# nrf9230_engb_application register map
Vendor: Nordic Semiconductor; Series: nRF92; File version: 1
CPU: CM33 r0p4, little endian, MPU, FPU, 3 interrupt priority bits, 480 interrupts, 4 SAU regions
Registers are 32-bit, read-write, reset 0x0 unless marked. A register's access mark holds for its fields unless they carry their own. Offsets are from the block's base; [hi:lo] are bit positions; 'fields as' and 'values as' point back to an identical list.

## GLOBAL_MCAN120_NS — MCAN 0
Base 0x2FBEF800; alternate view of GLOBAL_DMU120_NS
Same registers: GLOBAL_MCAN121_NS 0x2FBF7800 (alternate view of GLOBAL_DMU121_NS)
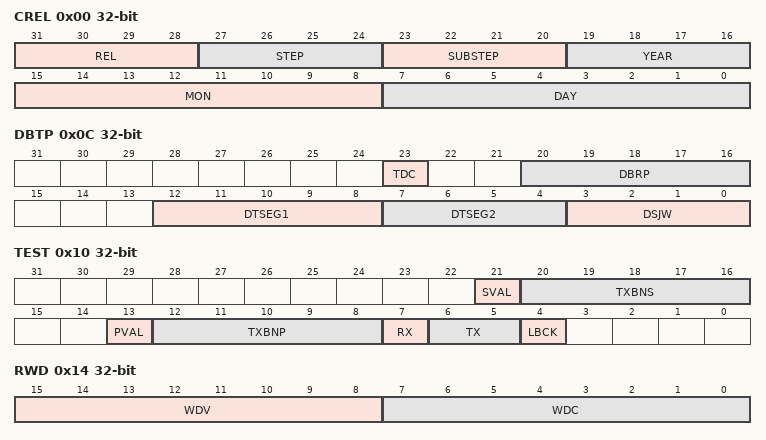
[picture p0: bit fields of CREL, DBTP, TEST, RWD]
0x00 CREL ro — Core Release Register
  [31:28] REL — Core Release
  [27:24] STEP — Step of Core Release
  [23:20] SUBSTEP — Sub-step of Core Release
  [19:16] YEAR — Time Stamp Year
  [15:8] MON — Time Stamp Month
  [7:0] DAY — Time Stamp Day
0x04 ENDN ro — Endian Register
  [31:0] ETV — Endianness Test Value
0x08 CUST — Customer Register
0x0C DBTP — Data Bit Timing and Prescaler Register
  [23] TDC — Transmitter Delay Compensation
    0=Disabled (Unspecified); 1=Enabled (Unspecified)
  [20:16] DBRP — Data Bit Rate Prescaler
  [12:8] DTSEG1 — Data time segment before sample point
  [7:4] DTSEG2 — Data time segment after sample point
  [3:0] DSJW — Data (Re)Synchronization Jump Width
0x10 TEST
  [21] SVAL — Started Valid
    0=NotValid (Value of TXBNP not valid); 1=Valid (Value of TXBNP valid)
  [20:16] TXBNS — Tx Buffer Number Started
  [13] PVAL — Prepared Valid
    values as SVAL
  [12:8] TXBNP — Tx Buffer Number Prepared
  [7] RX — Receive Pin
    0=Dominant (The CAN bus is dominant (m_can_rx = 0)); 1=Recessive (The CAN bus is recessive (m_can_rx = '1'))
  [6:5] TX — Control of Transmit Pin
    0=CanCore (controlled by the CAN Core, updated at the end of the CAN bit time); 1=Monitored (Sample Point can be monitored at pin m_can_tx); 2=Dominant (0) level at pin m_can_tx; 3=Recessive (1) at pin m_can_tx
  [4] LBCK — Loop Back Mode
    0=Disabled (Loop Back Mode is disabled); 1=Enabled (Loop Back Mode is enabled)
0x14 RWD — RAM Watchdog
  [15:8] WDV — Actual Message RAM Watchdog Counter Value.
  [7:0] WDC — Start value of the Message RAM Watchdog Counter. With the reset value of '00' the counter is disabled.
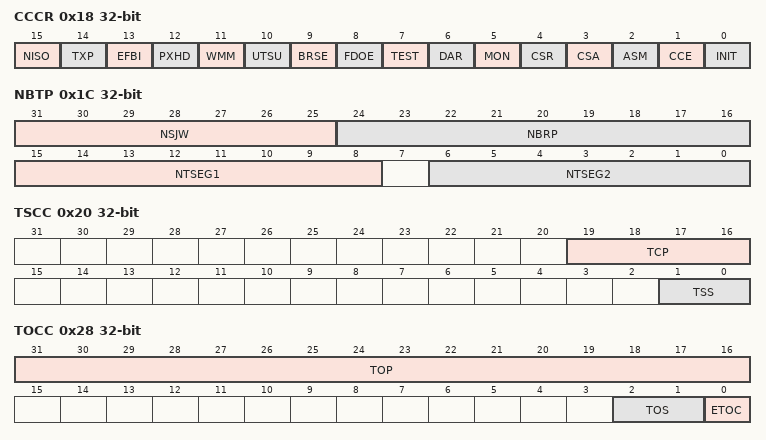
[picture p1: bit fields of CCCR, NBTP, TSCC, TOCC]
0x18 CCCR — CC Control Register
  [15] NISO — Non ISO Operation
    0=Disabled (CAN FD frame format according to ISO 11898-1:2015); 1=Enabled (CAN FD frame format according to Bosch CAN FD Specification V1.0)
  [14] TXP — Transmit Pause
    0=Disabled (Transmit pause disabled); 1=Enabled (Transmit pause enabled)
  [13] EFBI — Edge Filtering during Bus Integration
    0=Disabled (Edge filtering disabled); 1=Enabled (Two consecutive dominant tq required to detect an edge for hard synchronization)
  [12] PXHD — Protocol Exception Handling Disable
    0=Enabled (Protocol exception handling enabled); 1=Disabled (Protocol exception handling disabled)
  [11] WMM — Wide Message Marker
    0=Disabled (8-bit Message Marker used); 1=Enabled (16-bit Message Marker used, replacing 16-bit timestamps in Tx Event FIFO)
  [10] UTSU — Use Timestamping Unit
    0=Disabled (Internal time stamping); 1=Enabled (External time stamping by TSU)
  [9] BRSE — Bit Rate Switch Enable
    0=Disabled (Bit rate switching for transmissions disabled); 1=Enabled (Bit rate switching for transmissions enabled)
  [8] FDOE — FD Operation Enable
    0=Disabled (FD operation disabled); 1=Enabled (FD operation enabled)
  [7] TEST — Test Mode Enable
    0=Disabled (Normal operation, register TEST holds reset values); 1=Enabled (Test Mode, write access to register TEST enabled)
  [6] DAR — Disable Automatic Retransmission
    0=Enabled (Automatic retransmission of messages not transmitted successfully enabled); 1=Disabled (Automatic retransmission disabled)
  [5] MON — Bus Monitoring Mode
    0=Disabled (Bus Monitoring Mode is disabled); 1=Enabled (Bus Monitoring Mode is enabled)
  [4] CSR — Clock Stop Request
    0=Disabled (No clock stop is requested); 1=Enabled (Clock stop requested.)
  [3] CSA — Clock Stop Acknowledge
    0=Disabled (No clock stop acknowledged); 1=Enabled (MCAN may be set in power down by stopping m_can_hclk and m_can_cclk)
  [2] ASM — Restricted Operation Mode
    0=Disabled (Normal CAN operation); 1=Enabled (Restricted Operation Mode active)
  [1] CCE — Configuration Change Enable
    0=Disabled (The CPU has no write access to the protected configuration registers); 1=Enabled (The CPU has write access to the protected configuration registers (while CCCR.INIT = '1'))
  [0] INIT — Initialization
    0=Normal Operation; 1=Initialization is started
0x1C NBTP — Nominal Bit Timing and Prescaler Register
  [31:25] NSJW — Nominal (Re)Synchronization Jump Width
  [24:16] NBRP — Nominal Bit Rate Prescaler
  [15:8] NTSEG1 — Nominal Time segment before sample point
  [6:0] NTSEG2 — Nominal Time segment after sample point
0x20 TSCC — Timestamp Counter Configuration
  [19:16] TCP — Timestamp Counter Prescaler
  [1:0] TSS — Timestamp Select
    0=Zero (Timestamp counter value always 0x0000); 1=Increment (Timestamp counter value incremented according to TCP); 2=External timestamp counter value used; 3=Zero0 (Same as Zero)
0x24 TSCV — Timestamp Counter Value
  [15:0] TSC — Timestamp Counter
0x28 TOCC — Timeout Counter Configuration
  [31:16] TOP — Timeout Period
  [2:1] TOS — Timeout Select
    0=Continuous operation; 1=TxEvent (Timeout controlled by Tx Event FIFO); 2=RxFifo0 (Timeout controlled by Rx FIFO 0); 3=RxFifo1 (Timeout controlled by Rx FIFO 1)
  [0] ETOC — Enable Timeout Counter
    0=Disabled (Timeout Counter disabled); 1=Enabled (Timeout Counter enabled)
0x2C TOCV — Timeout Counter Value
  [15:0] TOC — Timeout Counter
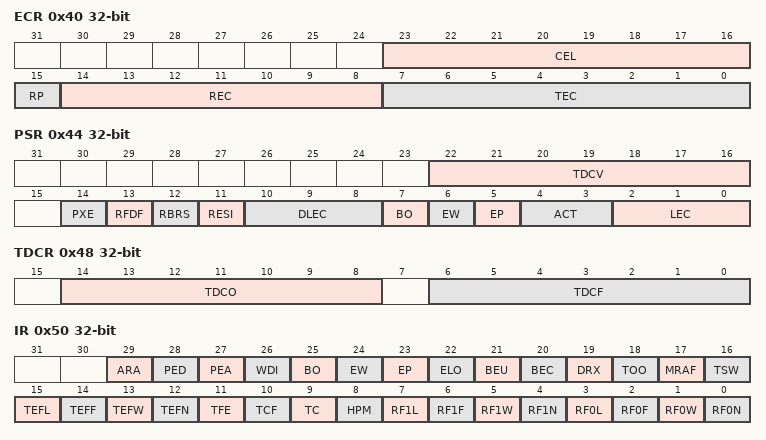
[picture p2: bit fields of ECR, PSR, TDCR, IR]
0x40 ECR — Error Counter Register
  [23:16] CEL — CAN Error Logging
  [15] RP — Receive Error Passive
    0=Below (The Receive Error Counter is below the error passive level of 128); 1=Reached (The Receive Error Counter has reached the error passive level of 128)
  [14:8] REC — Receive Error Counter
  [7:0] TEC — Transmit Error Counter
0x44 PSR — Protocol Status Register
  [22:16] TDCV — Transmitter Delay Compensation Value
  [14] PXE — Protocol Exception Event
    0=NotTriggered (No protocol exception event occurred since last read access); 1=Triggered (Protocol exception event occurred)
  [13] RFDF — Received a CAN FD Message
    0=NotReceived (Since this bit was reset by the CPU, no CAN FD message has been received); 1=Received (Message in CAN FD format with FDF flag set has been received)
  [12] RBRS — BRS flag of last received CAN FD Message
    0=NotReceived (Last received CAN FD message did not ha ve its BRS flag set); 1=Received (Last received CAN FD message had its BRS flag set)
  [11] RESI — ESI flag of last received CAN FD Message
    0=NotReceived (Last received CAN FD message did not ha ve its ESI flag set); 1=Received (Last received CAN FD message had its ESI flag set)
  [10:8] DLEC — Data Phase Last Error Code
  [7] BO — Bus_Off Status
    0=On (The MCAN is not Bus_Off); 1=Off (The MCAN is in Bus_Off state)
  [6] EW — Warning Status
    0=Below (Both error counters are below the Error_Warning limit of 96); 1=Reached (At least one of error counter has reached the Error_Warning limit of 96)
  [5] EP — Error Passive
    0=Active (The MCAN is in the Error_Active state. It normally takes part in bus communication and sends an active error flag when an error has been detected); 1=Passive (The MCAN is in the Error_Passive state)
  [4:3] ACT — Activity
    0=Synchronizing (Node is synchronizing on CAN communication); 1=Idle (Node is neither receiver nor tr ansmitter); 2=Receiver (Node is operating as receiver); 3=Transmitter (Node is operating as transmitter)
  [2:0] LEC — Last Error Code
    0=No error occurred since LEC has been reset by successful reception or transmission; 1=StuffError (More than 5 equal bits in a sequence have occurred in a part of a received message where this is not allowed.); 2=FormError (A fixed format part of a received frame has the wrong format.); 3=AckError (The message transmitted by the MCAN was not acknowledged by another node.); 4=Bit1Error (During the transmission of a message (with the exception of the arbitration field), the device wanted to send a recessive level (bit of logical value 1), but the monitored bus value was dominant.); 5=Bit0Error (During the transmission of a message (or acknowledge bit, or active error flag, or overload flag), the device wanted to send a dominant level (data or identifier bit logical value '0'), but the monitored bus value was recessive. During Bus_Off recovery this status is set each time a sequence of 11 recessive bits has been monitored. This enables the CPU to monitor the proceeding of the Bus_Off recovery sequence (indicating the bus is not stuck at dominant or continuously disturbed).); 6=CRCError (The CRC check sum of a received message was incorrect. The CRC of an incoming message does not match with the CRC calculated from the received data.); 7=NoChange (Any read access to the Protocol Status Register re-initializes the LEC to '7'. When the LEC shows the value '7', no CAN bus event was detected since the last CPU read access to the Protocol Status Register.)
0x48 TDCR — Transmitter Delay Compensation Register
  [14:8] TDCO — Transmitter Delay Compensation SSP Offset
  [6:0] TDCF — Transmitter Delay Compensation Filter Window Length
0x50 IR — Interrupt Register
  [29] ARA — Access to Reserved Address
    1=Clear (Write '1' to clear interrupt flag); 0=NotGenerated (No access to reserved address occurred); 1=Generated (Access to reserved address occurred)
  [28] PED — Protocol Error in Data Phase (Data Bit Time is used)
    1=Clear (Write '1' to clear interrupt flag); 0=NotGenerated (No protocol error in data phase); 1=Generated (Protocol error in data phase detected (PSR.DLEC ≠ 0,7))
  [27] PEA — Protocol Error in Arbitration Phase (Nominal Bit Time is used)
    1=Clear (Write '1' to clear interrupt flag); 0=NotGenerated (No protocol error in arbitration phase); 1=Generated (Protocol error in arbitration phase detected (PSR.LEC ≠ 0,7))
  [26] WDI — Watchdog Interrupt
    1=Clear (Write '1' to clear interrupt flag); 0=NotGenerated (No Message RAM Watchdog event occurred); 1=Generated (Message RAM Watchdog event due to missing READY)
  [25] BO — Bus_Off Status
    1=Clear (Write '1' to clear interrupt flag); 0=NotGenerated (Bus_Off status unchanged); 1=Generated (Bus_Off status changed)
  [24] EW — Warning Status
    1=Clear (Write '1' to clear interrupt flag); 0=NotGenerated (Error_Warning status unchanged); 1=Generated (Error_Warning status changed)
  [23] EP — Error Passive
    1=Clear (Write '1' to clear interrupt flag); 0=NotGenerated (Error_Passive status unchanged); 1=Generated (Error_Passive status changed)
  [22] ELO — Error Logging Overflow
    1=Clear (Write '1' to clear interrupt flag); 0=NotGenerated (CAN Error Logging Counter did not overflow); 1=Generated (Overflow of CAN Error Logging Counter occurred)
  [21] BEU — Bus Error Uncorrected
    1=Clear (Write '1' to clear interrupt flag); 0=NotGenerated (No read slave error detected when reading from Message RAM); 1=Generated (Read slave error detected)
  [20] BEC — Bit Error Corrected
    1=Clear (Write '1' to clear interrupt flag); 0=NotGenerated (No bit error detected when reading from Message RAM); 1=Generated (Bit error detected and corrected (e.g. ECC))
  [19] DRX — Message stored to Dedicated Rx Buffer
    1=Clear (Write '1' to clear interrupt flag); 0=NotGenerated (No Rx Buffer updated); 1=Generated (At least one received message stored into an Rx Buff er)
  [18] TOO — Timeout Occurred
    1=Clear (Write '1' to clear interrupt flag); 0=NotGenerated (No timeout); 1=Generated (Timeout reached)
  [17] MRAF — Message RAM Access Failure
    1=Clear (Write '1' to clear interrupt flag); 0=NotGenerated (No Message RAM access failure occurred); 1=Generated (Message RAM access failure occurred)
  [16] TSW — Timestamp Wraparound
    1=Clear (Write '1' to clear interrupt flag); 0=NotGenerated (No timestamp counter wrap-around); 1=Generated (Timestamp counter wrapped around)
  [15] TEFL — Tx Event FIFO Element Lost
    1=Clear (Write '1' to clear interrupt flag); 0=NotGenerated (No Tx Event FIFO element lost); 1=Generated (Tx Event FIFO element lost, also set after wr ite attempt to Tx Event FIFO of siz e zero)
  [14] TEFF — Tx Event FIFO Full
    1=Clear (Write '1' to clear interrupt flag); 0=NotGenerated (Tx Event FIFO not full); 1=Generated (Tx Event FIFO full)
  [13] TEFW — Tx Event FIFO Watermark Reached
    1=Clear (Write '1' to clear interrupt flag); 0=NotGenerated (Tx Event FIFO fill level below watermark); 1=Generated (Tx Event FIFO fill level reached watermark)
  [12] TEFN — Tx Event FIFO New Entry
    1=Clear (Write '1' to clear interrupt flag); 0=NotGenerated (Tx Event FIFO unchanged); 1=Generated (Tx Handler wrote Tx Event FIFO element)
  [11] TFE — Tx FIFO Empty
    1=Clear (Write '1' to clear interrupt flag); 0=NotGenerated (Tx FIFO non-empty); 1=Generated (Tx FIFO empty)
  [10] TCF — Transmission Cancellation Finished
    1=Clear (Write '1' to clear interrupt flag); 0=NotGenerated (No transmission cancellation finished); 1=Generated (Transmission cancellation finished)
  [9] TC — Transmission Completed
    1=Clear (Write '1' to clear interrupt flag); 0=NotGenerated (No transmission completed); 1=Generated (Transmission completed)
  [8] HPM — High Priority Message
    1=Clear (Write '1' to clear interrupt flag); 0=NotGenerated (No high priority message received); 1=Generated (High priority message received)
  [7] RF1L — Rx FIFO 1 Message Lost
    1=Clear (Write '1' to clear interrupt flag); 0=NotGenerated (No Rx FIFO 1 message lost); 1=Generated (Rx FIFO 1 message lost, also set after write attempt to Rx FIFO 1 of size zero)
  [6] RF1F — Rx FIFO 1 Full
    1=Clear (Write '1' to clear interrupt flag); 0=NotGenerated (Rx FIFO 1 not full); 1=Generated (Rx FIFO 1 full)
  [5] RF1W — Rx FIFO 1 Watermark Reached
    1=Clear (Write '1' to clear interrupt flag); 0=NotGenerated (Rx FIFO 1 fill level below watermark); 1=Generated (Rx FIFO 1 fill level reached watermark)
  [4] RF1N — Rx FIFO 1 New Message
    1=Clear (Write '1' to clear interrupt flag); 0=NotGenerated (No new message written to Rx FIFO 1); 1=Generated (New message written to Rx FIFO 1)
  [3] RF0L — Rx FIFO 0 Message Lost
    1=Clear (Write '1' to clear interrupt flag); 0=NotGenerated (No Rx FIFO 0 message lost); 1=Generated (Rx FIFO 0 message lost, also set after write attempt to Rx FIFO 0 of size zero)
  [2] RF0F — Rx FIFO 0 Full
    1=Clear (Write '1' to clear interrupt flag); 0=NotGenerated (Rx FIFO 0 not full); 1=Generated (Rx FIFO 0 full)
  [1] RF0W — Rx FIFO 0 Watermark Reached
    1=Clear (Write '1' to clear interrupt flag); 0=NotGenerated (Rx FIFO 0 fill level below watermark); 1=Generated (Rx FIFO 0 fill level reached watermark)
  [0] RF0N — Rx FIFO 0 New Message
    1=Clear (Write '1' to clear interrupt flag); 0=NotGenerated (No new message written to Rx FIFO 0); 1=Generated (New message written to Rx FIFO 0)
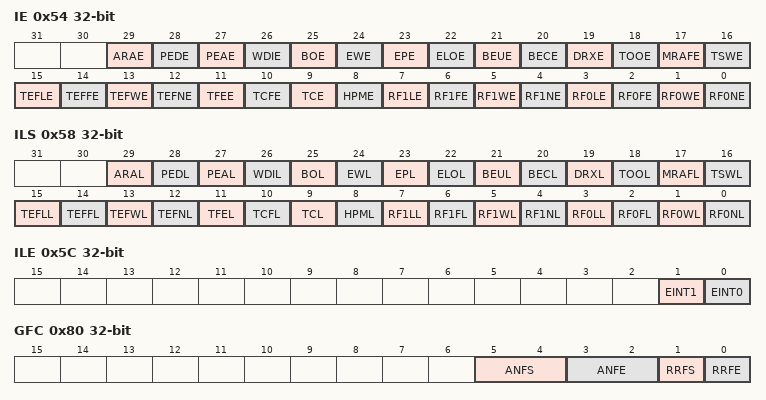
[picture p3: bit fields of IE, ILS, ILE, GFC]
0x54 IE — Interrupt Enable
  [all] fields
    0=Disable (Interrupt disabled.); 1=Enable (Interrupt enabled.)
  [29] ARAE — Access to Reserved Address Enable
  [28] PEDE — Protocol Error in Data Phase Enable
  [27] PEAE — Protocol Error in Arbitration Phase Enable
  [26] WDIE — Watchdog Interrupt Enable
  [25] BOE — Bus_Off Status Interrupt Enable
  [24] EWE — Warning Status Interrupt Enable
  [23] EPE — Error Passive Interrupt Enable
  [22] ELOE — Error Logging Overflow Interrupt Enable
  [21] BEUE — Bus Error Uncorrected Interrupt Enable
  [20] BECE — Bit Error Corrected Interrupt Enable
  [19] DRXE — Message stored to Dedicated Rx Buffer Interrupt Enable
  [18] TOOE — Timeout Occurred Interrupt Enable
  [17] MRAFE — Message RAM Access Failure Interrupt Enable
  [16] TSWE — Timestamp Wraparound Interrupt Enable
  [15] TEFLE — Tx Event FIFO Event Lost Interrupt Enable
  [14] TEFFE — Tx Event FIFO Full Interrupt Enable
  [13] TEFWE — Tx Event FIFO Watermark Reached Interrupt Enable
  [12] TEFNE — Tx Event FIFO New Entry Interrupt Enable
  [11] TFEE — Tx FIFO Empty Interrupt Enable
  [10] TCFE — Transmission Cancellation Finished Interrupt Enable
  [9] TCE — Transmission Completed Interrupt Enable
  [8] HPME — High Priority Message Interrupt Enable
  [7] RF1LE — Rx FIFO 1 Message Lost Interrupt Enable
  [6] RF1FE — Rx FIFO 1 Full Interrupt Enable
  [5] RF1WE — Rx FIFO 1 Watermark Reached Interrupt Enable
  [4] RF1NE — Rx FIFO 1 New Message Interrupt Enable
  [3] RF0LE — Rx FIFO 0 Message Lost Interrupt Enable
  [2] RF0FE — Rx FIFO 0 Full Interrupt Enable
  [1] RF0WE — Rx FIFO 0 Watermark Reached Interrupt Enable
  [0] RF0NE — Rx FIFO 0 New Message Interrupt Enable
0x58 ILS — Interrupt Line Select
  [all] fields
    0=Assigned0 (Interrupt assigned to interrupt line CORE0.); 1=Assigned1 (Interrupt assigned to interrupt line CORE1.)
  [29] ARAL — Access to Reserved Address Line
  [28] PEDL — Protocol Error in Data Phase Line
  [27] PEAL — Protocol Error in Arbitration Phase Line
  [26] WDIL — Watchdog Interrupt Line
  [25] BOL — Bus_Off Status Interrupt Line
  [24] EWL — Warning Status Interrupt Line
  [23] EPL — Error Passive Interrupt Line
  [22] ELOL — Error Logging Overflow Interrupt Line
  [21] BEUL — Bus Error Uncorrected Interrupt Line
  [20] BECL — Bit Error Corrected Interrupt Line
  [19] DRXL — Message stored to Dedicated Rx Buffer Interrupt Line
  [18] TOOL — Timeout Occurred Interrupt Line
  [17] MRAFL — Message RAM Access Failure Interrupt Line
  [16] TSWL — Timestamp Wraparound Interrupt Line
  [15] TEFLL — Tx Event FIFO Event Lost Interrupt Line
  [14] TEFFL — Tx Event FIFO Full Interrupt Line
  [13] TEFWL — Tx Event FIFO Watermark Reached Interrupt Line
  [12] TEFNL — Tx Event FIFO New Entry Interrupt Line
  [11] TFEL — Tx FIFO Empty Interrupt Line
  [10] TCFL — Transmission Cancellation Finished Interrupt Line
  [9] TCL — Transmission Completed Interrupt Line
  [8] HPML — High Priority Message Interrupt Line
  [7] RF1LL — Rx FIFO 1 Message Lost Interrupt Line
  [6] RF1FL — Rx FIFO 1 Full Interrupt Line
  [5] RF1WL — Rx FIFO 1 Watermark Reached Interrupt Line
  [4] RF1NL — Rx FIFO 1 New Message Interrupt Line
  [3] RF0LL — Rx FIFO 0 Message Lost Interrupt Line
  [2] RF0FL — Rx FIFO 0 Full Interrupt Line
  [1] RF0WL — Rx FIFO 0 Watermark Reached Interrupt Line
  [0] RF0NL — Rx FIFO 0 New Message Interrupt Line
0x5C ILE — Interrupt Line Enable
  [1] EINT1 — Enable Interrupt Line 1
    0=Disable (Interrupt line CORE1 disabled.); 1=Enable (Interrupt line CORE1 enabled.)
  [0] EINT0 — Enable Interrupt Line 0
    0=Disable (Interrupt line CORE0 disabled.); 1=Enable (Interrupt line CORE0 enabled.)
0x80 GFC — Global Filter Configuration
  [5:4] ANFS
    0=Accept0 (Accept in Rx FIFO 0.); 1=Accept1 (Accept in Rx FIFO 1.); 2=Reject0 (Reject in both Rx FIFOs.); 3=Reject1 (Reject in both Rx FIFOs.)
  [3:2] ANFE — Accept Non-matching Frames Extended
    values as ANFS
  [1] RRFS — Reject Remote Frames Standard
    0=Filter remote frames with 11-bit standard IDs; 1=Reject all remote frames with 11-bit standard IDs
  [0] RRFE — Reject Remote Frames Extended
    0=Filter remote frames with 29-bit extended IDs; 1=Reject all remote frames with 29-bit extended IDs
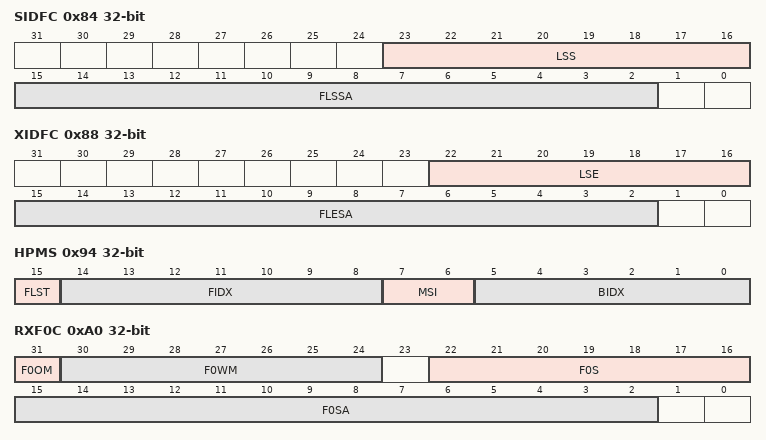
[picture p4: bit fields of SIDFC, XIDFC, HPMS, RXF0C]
0x84 SIDFC — Standard ID Filter Configuration
  [23:16] LSS — List Size Standard
  [15:2] FLSSA — Filter List Standard Start Address
0x88 XIDFC — Extended ID Filter Configuration
  [22:16] LSE — List Size Extended
  [15:2] FLESA — Filter List Extended Start Address
0x90 XIDAM — Extended ID AND Mask
  [28:0] EIDM — Extended ID Mask
0x94 HPMS ro — High Priority Message Status
  [15] FLST — Filter List
    0=Standard Filter List; 1=Extended Filter List
  [14:8] FIDX — Filter Index
  [7:6] MSI — Message Storage Indicator
    0=NotSelected (No FIFO selected.); 1=Lost (FIFO message lost.); 2=Stored0 (Message stored in FIFO 0.); 3=Stored1 (Message stored in FIFO 1.)
  [5:0] BIDX — Buffer Index
0x98 NDAT1 — New Data 1
  [31:0] ND — New Data
    0=NotUpdated (Rx Buffer not updated.); 1=Updated (Rx Buffer updated from new message.)
0x9C NDAT2 — New Data 2
  fields as NDAT1
0xA0 RXF0C — Rx FIFO 0 Configuration
  [31] F0OM — FIFO 0 Operation Mode
    0=Blocking (FIFO 0 blocking mode.); 1=Overwrite (FIFO 0 overwrite mode.)
  [30:24] F0WM — Rx FIFO 0 Watermark
  [22:16] F0S — Rx FIFO 0 Size
  [15:2] F0SA — Rx FIFO 0 Start Address
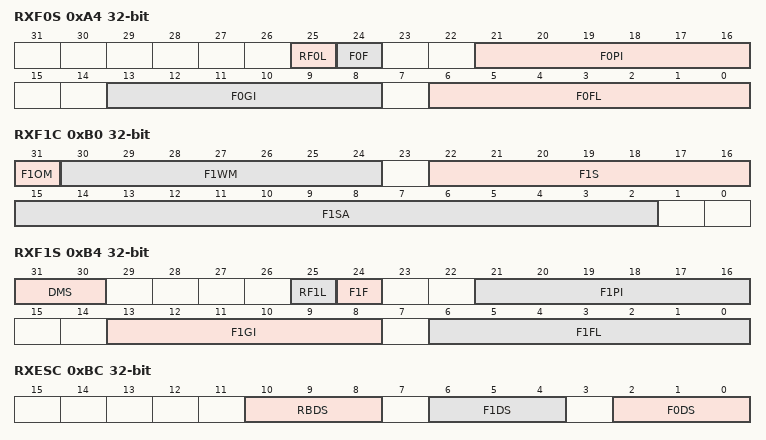
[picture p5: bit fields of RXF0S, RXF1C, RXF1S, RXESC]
0xA4 RXF0S ro — Rx FIFO 0 Status
  [25] RF0L — Rx FIFO 0 Message Lost
    0=NotLost (No Rx FIFO 0 message lost.); 1=Lost (Rx FIFO 0 message lost, also set after write attempt to Rx FIFO 0 of size zero.)
  [24] F0F — Rx FIFO 0 Full
    0=NotFull (Rx FIFO 0 not full.); 1=Full (Rx FIFO 0 full.)
  [21:16] F0PI — Rx FIFO 0 Put Index
  [13:8] F0GI — Rx FIFO 0 Get Index
  [6:0] F0FL — Rx FIFO 0 Fill Leve
0xA8 RXF0A — Rx FIFO 0 Acknowledge
  [5:0] F0AI — Rx FIFO 0 Acknowledge Index
0xAC RXBC — Rx Buffer Configuration
  [15:2] RBSA — Rx Buffer Start Address
0xB0 RXF1C — Rx FIFO 1 Configuration
  [31] F1OM — FIFO 1 Operation Mode
    0=BlockingMode (FIFO 1 blocking mode); 1=OwerwriteMode (FIFO 1 overwrite mode)
  [30:24] F1WM — Rx FIFO 1 Watermark
  [22:16] F1S — Rx FIFO 1 Size
  [15:2] F1SA — Rx FIFO 1 Start Address
0xB4 RXF1S ro — Rx FIFO 1 Status
  [31:30] DMS — Debug Message Status
    0=Idle state, wait for reception of debug messages, DMA request is cleared; 1=ReceivedMesA (Debug message A received); 2=ReceivedMesAB (Debug messages A, B received); 3=ReceivedMesABC (Debug messages A, B, C received, DMA request is set)
  [25] RF1L — Rx FIFO 1 Message Lost
    0=NoMessageLost (No Rx FIFO 1 message lost); 1=MessageLost (Rx FIFO 1 message lost, also set after write attempt to Rx FIFO 1 of size zero)
  [24] F1F — Rx FIFO 1 Full
    0=NotFull (Rx FIFO 1 not full); 1=Full (Rx FIFO 1 full)
  [21:16] F1PI — Rx FIFO 1 Put Index
  [13:8] F1GI — Rx FIFO 1 Get Index
  [6:0] F1FL — Rx FIFO 1 Fill Level
0xB8 RXF1A — Rx FIFO 1 Acknowledge
  [5:0] F1AI — Rx FIFO 1 Acknowledge Index
0xBC RXESC — Rx Buffer / FIFO Element Size Configuration
  [all] fields
    0=DataField8B (8 byte data field); 1=DataField12B (12 byte data field); 2=DataField16B (16 byte data field); 3=DataField20B (20 byte data field); 4=DataField24B (24 byte data field); 5=DataField32B (32 byte data field); 6=DataField48B (48 byte data field); 7=DataField64B (64 byte data field)
  [10:8] RBDS — Rx Buffer Data Field Size
  [6:4] F1DS — Rx FIFO 1 Data Field Size
  [2:0] F0DS — Rx FIFO 0 Data Field Size
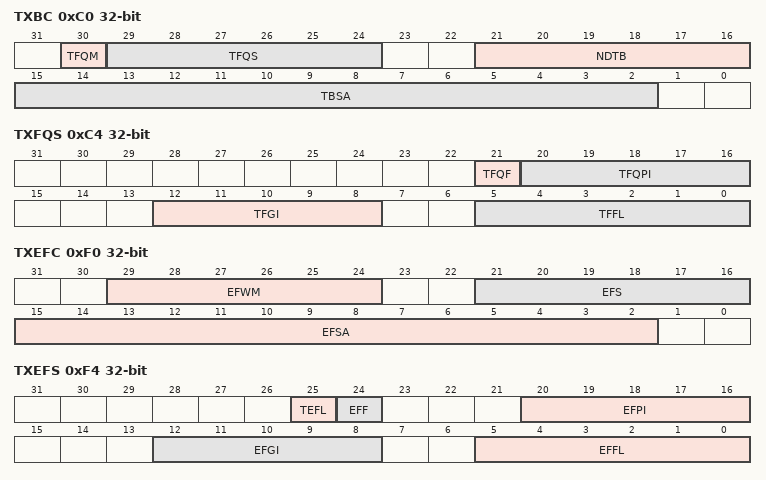
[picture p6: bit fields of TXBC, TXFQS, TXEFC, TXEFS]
0xC0 TXBC — Tx Buffer Configuration
  [30] TFQM — Tx FIFO/Queue Mode
    0=Tx FIFO operation; 1=Tx Queue operation
  [29:24] TFQS — Transmit FIFO/Queue Size
  [21:16] NDTB — Number of Dedicated Transmit Buffers
  [15:2] TBSA — Tx Buffers Start Address
0xC4 TXFQS ro — Tx FIFO/Queue Status
  [21] TFQF — Tx FIFO/Queue Full
    0=NotFull (Tx FIFO/Queue not full); 1=Full (Tx FIFO/Queue full)
  [20:16] TFQPI — Tx FIFO/Queue Put Index
  [12:8] TFGI — Tx FIFO Get Index
  [5:0] TFFL — Tx FIFO Free Level
0xC8 TXESC — Tx Buffer Element Size Configuration
  [2:0] TBDS — Tx Buffer Data Field Size
    values as the fields of RXESC
0xCC TXBRP ro — Tx Buffer Request Pending
  [31:0] TRP — Transmission Request Pending
    0=NoRequest (No transmission request pending); 1=Request (Transmission request pending)
0xD0 TXBAR — Tx Buffer Add Request
  [31:0] AR — Add Request
    0=NoRequest (No transmission request added); 1=Request (Transmission requested added)
0xD4 TXBCR — Tx Buffer Cancellation Request
  [31:0] CR — Cancellation Request
    0=No cancellation pending; 1=Cancellation pending
0xD8 TXBTO ro — Tx Buffer Transmission Occurred
  [31:0] TO — Transmission Occurred
    0=NoTransmittion (No transmission occurred); 1=Transmittion (Transmission occurred)
0xDC TXBCF ro — Tx Buffer Cancellation Finished
  [31:0] CF — Cancellation Finished
    0=NoCancellation (No transmit buffer cancellation); 1=CancellationFinished (Transmit buffer cancellation finished)
0xE0 TXBTIE — Tx Buffer Transmission Interrupt Enable
  [31:0] TIE — Transmission Interrupt Enable
    0=Disable (Transmission interrupt disabled); 1=Enable (Transmission interrupt enable)
0xE4 TXBCIE — Tx Buffer Cancellation Finished Interrupt Enable
  [31:0] CFIE — Cancellation Finished Interrupt Enable
    0=Disable (Cancellation finished interrupt disabled); 1=Enable (Cancellation finished interrupt enabled)
0xF0 TXEFC — Tx Event FIFO Configuration
  [29:24] EFWM — Event FIFO Watermark
  [21:16] EFS — Event FIFO Size
  [15:2] EFSA — Event FIFO Start Address
0xF4 TXEFS ro — Tx Event FIFO Status
  [25] TEFL — Tx Event FIFO Element Lost
    0=NotLost (No Tx Event FIFO element lost); 1=Lost (Tx Event FIFO element lost, also set after wr ite attempt to Tx Event FIFO of siz e zero.)
  [24] EFF — Event FIFO Full
    0=NotFull (Tx Event FIFO not full); 1=Full (Tx Event FIFO full)
  [20:16] EFPI — Event FIFO Put Index
  [12:8] EFGI — Event FIFO Get Index
  [5:0] EFFL — Event FIFO Fill Level
0xF8 TXEFA — Tx Event FIFO Acknowledge
  [4:0] EFAI — Event FIFO Acknowledge Index

## Notices in the file
Copyright (c) 2010 - 2024, Nordic Semiconductor ASA
All rights reserved.
Redistribution and use in source and binary forms, with or without modification,
are permitted provided that the following conditions are met:
1. Redistributions of source code must retain the above copyright notice, this
list of conditions and the following disclaimer.
2. Redistributions in binary form, except as embedded into a Nordic
Semiconductor ASA integrated circuit in a product or a software update for
such product, must reproduce the above copyright notice, this list of
conditions and the following disclaimer in the documentation and/or other
materials provided with the distribution.
3. Neither the name of Nordic Semiconductor ASA nor the names of its
contributors may be used to endorse or promote products derived from this
software without specific prior written permission.
4. This software, with or without modification, must only be used with a
Nordic Semiconductor ASA integrated circuit.
5. Any software provided in binary form under this license must not be reverse
engineered, decompiled, modified and/or disassembled.
THIS SOFTWARE IS PROVIDED BY NORDIC SEMICONDUCTOR ASA "AS IS" AND ANY EXPRESS
OR IMPLIED WARRANTIES, INCLUDING, BUT NOT LIMITED TO, THE IMPLIED WARRANTIES
OF MERCHANTABILITY, NONINFRINGEMENT, AND FITNESS FOR A PARTICULAR PURPOSE ARE
DISCLAIMED. IN NO EVENT SHALL NORDIC SEMICONDUCTOR ASA OR CONTRIBUTORS BE
LIABLE FOR ANY DIRECT, INDIRECT, INCIDENTAL, SPECIAL, EXEMPLARY, OR
CONSEQUENTIAL DAMAGES (INCLUDING, BUT NOT LIMITED TO, PROCUREMENT OF SUBSTITUTE
GOODS OR SERVICES; LOSS OF USE, DATA, OR PROFITS; OR BUSINESS INTERRUPTION)
HOWEVER CAUSED AND ON ANY THEORY OF LIABILITY, WHETHER IN CONTRACT, STRICT
LIABILITY, OR TORT (INCLUDING NEGLIGENCE OR OTHERWISE) ARISING IN ANY WAY OUT
OF THE USE OF THIS SOFTWARE, EVEN IF ADVISED OF THE POSSIBILITY OF SUCH DAMAGE.
